# ZB32L030 register map
Vendor: ZBit.; Series: ZB32L03X; File version: 1.0
CPU: CM0+ r1p0, little endian, no MPU, no FPU, VTOR, 2 interrupt priority bits
Registers are 32-bit, read-write, reset 0x0 unless marked. A register's access mark holds for its fields unless they carry their own. Offsets are from the block's base; [hi:lo] are bit positions; {n}, {i} and the like mark numbered series; 'fields as' and 'values as' point back to an identical list.

## OBYTES — Option Bytes as user configuration
Base 0x08000000
0x00 USERCFG0 ro — user configuration
  [0] ISP_CON — ISP enable or not
0x04 USERCFG1 ro — user configuration
  [0] SWDP — SWD protection enable or not
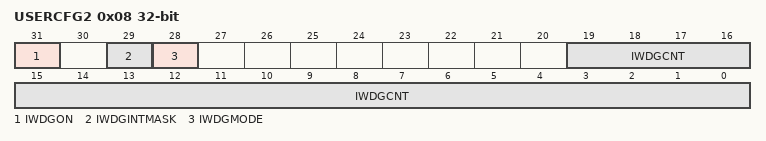
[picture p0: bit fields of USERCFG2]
0x08 USERCFG2 ro — user configuration
  [31] IWDGON — IWDG auto-enable or not
  [29] IWDGINTMASK — IWDG interrupt mask enable or not
  [28] IWDGMODE — IWDG mode, 0: reset, 1: interrupt
  [19:0] IWDGCNT — IWDG counter

## SYSCFG — system configuration of NVR
Base 0x18000000
0x00 WORD0380 ro reset 0x1 — system configuration
  [0] FULLSIZE — 0:32KB, 1: 64KB
    0=32KB (eFlash 32KBytes); 1=64KB (eFlash 64KBytes)
0x80 WORD03A0 ro — system configuration
  [31:0] CP3_MARK — CP3 mark, it should be 0x55AA6699 or 0x55AA0000
0x84 WORD03A1 ro — system configuration
  [31:0] FT_MARK — FT mark, it should be 0x5A5A6969
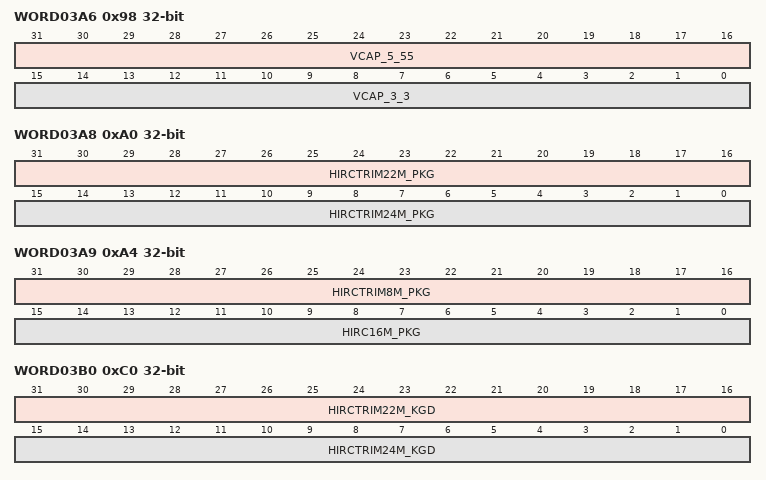
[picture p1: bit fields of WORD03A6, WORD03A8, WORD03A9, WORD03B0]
0x98 WORD03A6 ro — system configuration
  [31:16] VCAP_5_55 — Vcap of VDD 5.55V
  [15:0] VCAP_3_3 — Vcap of VDD 3.3V
0xA0 WORD03A8 ro — system configuration
  [31:16] HIRCTRIM22M_PKG — HIRC 22.12MHz trimming value
  [15:0] HIRCTRIM24M_PKG — HIRC 24MHz trimming value
0xA4 WORD03A9 ro — system configuration
  [31:16] HIRCTRIM8M_PKG — HIRC 8MHz trimming value
  [15:0] HIRC16M_PKG — HIRC 16MHz trimming value
0xA8 WORD03AA ro — system configuration
  [15:0] HIRCTRIM4M_PKG — HIRC 4MHz trimming value
0xB0 WORD03AC ro — system configuration
  [15:0] SIRCTRIM32K_PKG — SIRC 32KHz trimming value
0xB4 WORD03AD ro — system configuration
  [15:0] SIRCTRIM38K_PKG — SIRC 38KHz trimming value
0xC0 WORD03B0 ro — system configuration
  [31:16] HIRCTRIM22M_KGD — HIRC 22.12MHz trimming value
  [15:0] HIRCTRIM24M_KGD — HIRC 24MHz trimming value
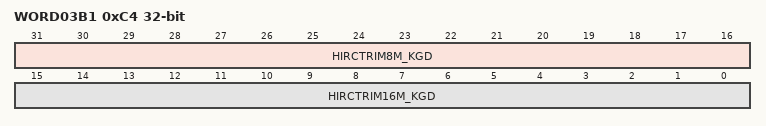
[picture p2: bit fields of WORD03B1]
0xC4 WORD03B1 ro — system configuration
  [31:16] HIRCTRIM8M_KGD — HIRC 8MHz trimming value
  [15:0] HIRCTRIM16M_KGD — HIRC 16MHz trimming value
0xC8 WORD03B2 ro — system configuration
  [15:0] HIRCTRIM4M_KGD — HIRC 4MHz trimming value
0xD0 WORD03B4 ro — system configuration
  [15:0] SIRCTRIM32K_KGD — SIRC 32KHz trimming value
0xD4 WORD03B5 ro — system configuration
  [15:0] SIRCTRIM38K_KGD — SIRC 38KHz trimming value
0xF0 WORD03BC ro — system configuration
  [31:0] UID0
0xF4 WORD03BD ro — system configuration
  [31:0] UID1
0xF8 WORD03BE ro — system configuration
  [31:0] UID2
0xFC WORD03BF ro — system configuration
  [31:0] UID3

## SYSCON — system control config
Base 0x40001C00
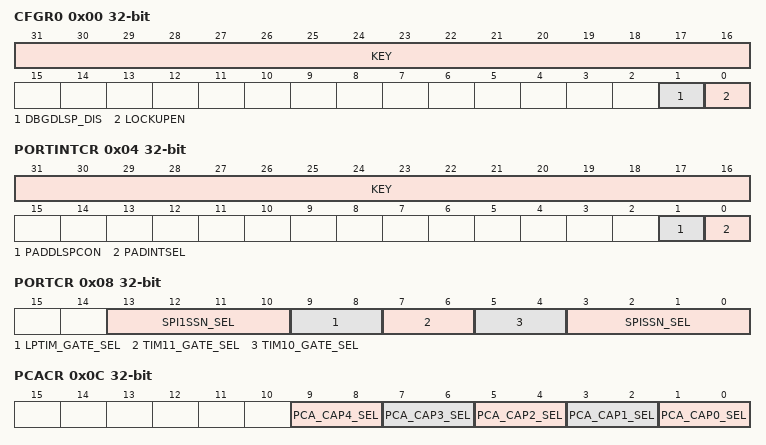
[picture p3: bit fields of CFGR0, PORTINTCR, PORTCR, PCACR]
0x00 CFGR0 — System Control setting regist 0
  [31:16] KEY wo
  [1] DBGDLSP_DIS — Allow Debug Enter DeepSleep Mode
  [0] LOCKUPEN — LOCKUP
0x04 PORTINTCR — Port interrupt mode setting
  [31:16] KEY wo
  [1] PADDLSPCON — PADDLSP
  [0] PADINTSEL — Endpoint Interrupt Mode Select
0x08 PORTCR — PORT control register
  [13:10] SPI1SSN_SEL — SPI1 Slave SSN source select
  [9:8] LPTIM_GATE_SEL — LPTIM GATE
  [7:6] TIM11_GATE_SEL — TIMER11 GATE
  [5:4] TIM10_GATE_SEL — TIMER10 GATE
  [3:0] SPISSN_SEL — SPI0 SSN source select
0x0C PCACR — PCA Capture channel source select
  [2n+1:2n] PCA_CAP{n}_SEL (n=0..4) — PCA Channel
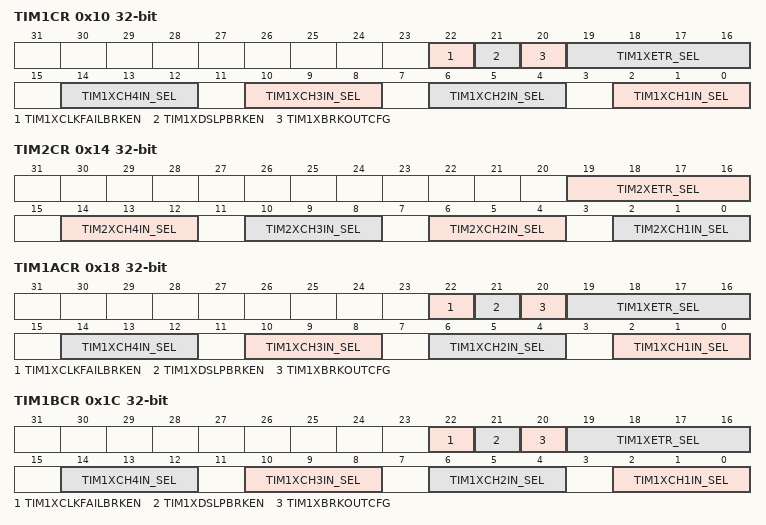
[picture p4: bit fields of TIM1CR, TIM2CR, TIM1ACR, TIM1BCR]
0x10 TIM1CR — TIM1 Channel Source Select
  [22] TIM1XCLKFAILBRKEN — TIM1x CLKFAILBRKE
  [21] TIM1XDSLPBRKEN
  [20] TIM1XBRKOUTCFG
  [19:16] TIM1XETR_SEL — TIM1x ETR source select
    0=DEF (Low level); 1=PA1 (PA1 pin); 2=PA2 (PA2 pin); 3=PA3 (PA3 pin); 4=PB4 (PB4 pin); 5=PB5 (PB5 pin); 6=PA0 (PA0 pin); 7=PD0 (PD0 pin); 8=PC5 (PC5 pin); 9=PC6 (PC6 pin); 10=PC7 (PC7 pin); 11=PD1 (PD1 pin); 12=PA03 (PA3 pin); 13=PA4 (PA4 pin); 14=PA5 (PA5 pin); 15=PA6 (PA6 pin)
  [4n-2:4n-4] TIM1XCH{n}IN_SEL (n=1..4) — TIM1x CH{n} input Source
    0=TIMX_CH{n}; 1=UART0_RXD; 2=UART1_RXD; 3=LPUART_RXD; 4=SIRC
0x14 TIM2CR — TIM2 Channel Source Select
  [19:16] TIM2XETR_SEL — TIM2X ETR Source Select
    values as TIM1CR.TIM1XETR_SEL
  [4n-2:4n-4] TIM2XCH{n}IN_SEL (n=1..4) — TIMX CH{n} input Source
    0=TIMX_CH{n}; 1=UART0_RXD; 2=UART1_RXD; 3=LPUART_RXD; 4=SIRC
0x18 TIM1ACR — TIM1A Channel Source Select
  [22] TIM1XCLKFAILBRKEN — TIM1x CLKFAILBRKE
  [21] TIM1XDSLPBRKEN
  [20] TIM1XBRKOUTCFG
  [19:16] TIM1XETR_SEL — TIMX ETR source select
    values as TIM1CR.TIM1XETR_SEL
  [4n-2:4n-4] TIM1XCH{n}IN_SEL (n=1..4) — TIMX CH{n} input Source
    0=TIMX_CH{n}; 1=UART0_RXD; 2=UART1_RXD; 3=LPUART_RXD; 4=SIRC
0x1C TIM1BCR — TIM1B Channel Source Select
  fields as TIM1ACR
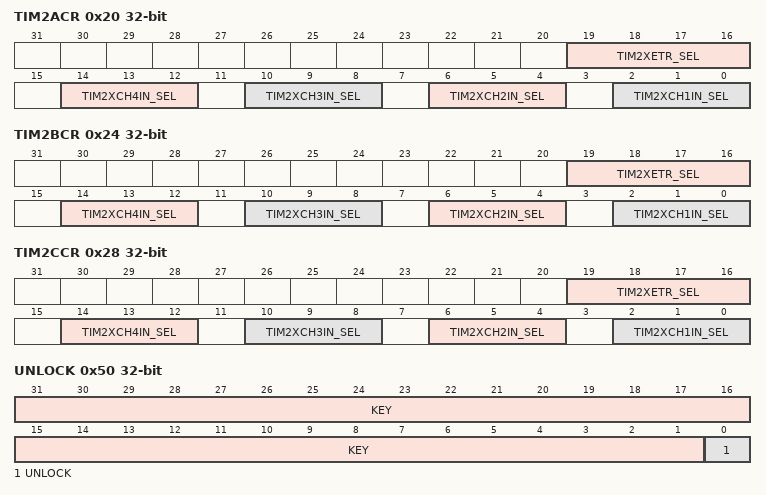
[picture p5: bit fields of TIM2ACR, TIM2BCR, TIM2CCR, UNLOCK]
0x20 TIM2ACR — TIM2A Channel Source Select
  fields as TIM2CR
0x24 TIM2BCR — TIM2B Channel Source Select
  fields as TIM2CR
0x28 TIM2CCR — TIM2C Channel Source Select
  fields as TIM2CR
0x50 UNLOCK — Syscon Register Write Enable
  [31:1] KEY wo — Auth Key, KEY=0x2AD5334C
  [0] UNLOCK
